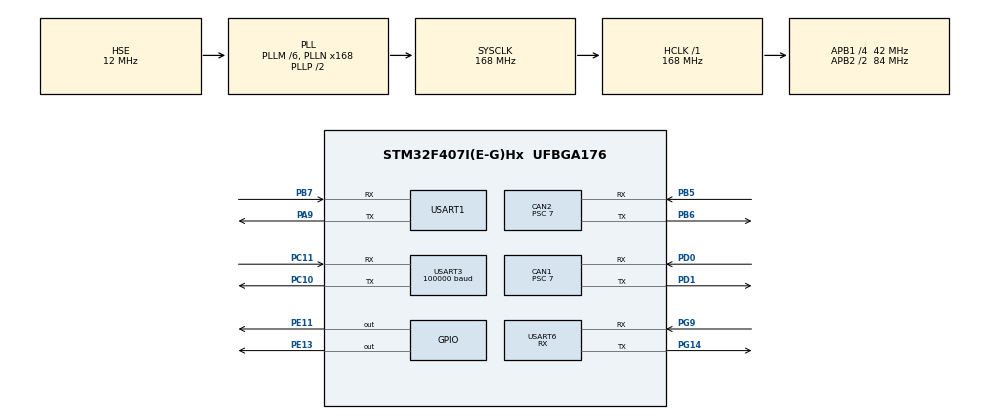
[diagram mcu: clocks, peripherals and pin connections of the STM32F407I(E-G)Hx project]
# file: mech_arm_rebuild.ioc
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CAN1.BS1=CAN_BS1_3TQ
CAN1.BS2=CAN_BS2_2TQ
CAN1.CalculateBaudRate=999999
CAN1.CalculateTimeBit=1000
CAN1.CalculateTimeQuantum=166.66666666666669
CAN1.Prescaler=7
CAN2.BS1=CAN_BS1_3TQ
CAN2.BS2=CAN_BS2_2TQ
CAN2.CalculateBaudRate=999999
CAN2.CalculateTimeBit=1000
CAN2.CalculateTimeQuantum=166.66666666666669
CAN2.Prescaler=7
Dma.Request0=USART3_RX
Dma.Request1=USART6_RX
Dma.USART3_RX.0.Direction=DMA_PERIPH_TO_MEMORY
Dma.USART3_RX.0.FIFOMode=DMA_FIFOMODE_DISABLE
Dma.USART3_RX.0.Instance=DMA1_Stream1
Dma.USART3_RX.0.MemDataAlignment=DMA_MDATAALIGN_BYTE
Dma.USART3_RX.0.MemInc=DMA_MINC_ENABLE
Dma.USART3_RX.0.Mode=DMA_NORMAL
Dma.USART3_RX.0.PeriphDataAlignment=DMA_PDATAALIGN_BYTE
Dma.USART3_RX.0.PeriphInc=DMA_PINC_DISABLE
Dma.USART3_RX.0.Priority=DMA_PRIORITY_LOW
Dma.USART6_RX.1.Direction=DMA_PERIPH_TO_MEMORY
Dma.USART6_RX.1.FIFOMode=DMA_FIFOMODE_DISABLE
Dma.USART6_RX.1.Instance=DMA2_Stream1
Dma.USART6_RX.1.MemDataAlignment=DMA_MDATAALIGN_BYTE
Dma.USART6_RX.1.MemInc=DMA_MINC_ENABLE
Dma.USART6_RX.1.Mode=DMA_NORMAL
Dma.USART6_RX.1.PeriphDataAlignment=DMA_PDATAALIGN_BYTE
Dma.USART6_RX.1.PeriphInc=DMA_PINC_DISABLE
Dma.USART6_RX.1.Priority=DMA_PRIORITY_LOW
Mcu.Family=STM32F4
Mcu.Name=STM32F407I(E-G)Hx
Mcu.Package=UFBGA176
NVIC.CAN1_RX0_IRQn=true\:0\:0\:false\:false\:true\:true\:true\:true
NVIC.CAN1_TX_IRQn=true\:0\:0\:false\:false\:true\:true\:true\:true
NVIC.CAN2_TX_IRQn=true\:0\:0\:false\:false\:true\:true\:true\:true
NVIC.DMA1_Stream1_IRQn=true\:0\:0\:false\:false\:true\:false\:true\:true
NVIC.DMA2_Stream1_IRQn=true\:0\:0\:false\:false\:true\:false\:true\:true
NVIC.PriorityGroup=NVIC_PRIORITYGROUP_4
NVIC.TIM3_IRQn=true\:0\:0\:false\:false\:true\:true\:true\:true
NVIC.TIM4_IRQn=true\:0\:0\:false\:false\:true\:true\:true\:true
NVIC.USART1_IRQn=true\:0\:0\:false\:false\:true\:true\:true\:true
NVIC.USART3_IRQn=true\:0\:0\:false\:false\:true\:true\:true\:true
NVIC.USART6_IRQn=true\:0\:0\:false\:false\:true\:true\:true\:true
PA13.Mode=Serial_Wire
PA13.Signal=SYS_JTMS-SWDIO
PA14.Mode=Serial_Wire
PA14.Signal=SYS_JTCK-SWCLK
PA9.Mode=Asynchronous
PA9.Signal=USART1_TX
PB5.Mode=CAN_Activate
PB5.Signal=CAN2_RX
PB6.Mode=CAN_Activate
PB6.Signal=CAN2_TX
PB7.Mode=Asynchronous
PB7.Signal=USART1_RX
PC10.Mode=Asynchronous
PC10.Signal=USART3_TX
PC11.Mode=Asynchronous
PC11.Signal=USART3_RX
PD0.Mode=CAN_Activate
PD0.Signal=CAN1_RX
PD1.Mode=CAN_Activate
PD1.Signal=CAN1_TX
PE11.Signal=GPIO_Output
PE13.Signal=GPIO_Output
PG14.Mode=Asynchronous
PG14.Signal=USART6_TX
PG9.Mode=Asynchronous
PG9.Signal=USART6_RX
PH0-OSC_IN.Mode=HSE-External-Oscillator
PH0-OSC_IN.Signal=RCC_OSC_IN
PH1-OSC_OUT.Mode=HSE-External-Oscillator
PH1-OSC_OUT.Signal=RCC_OSC_OUT
ProjectManager.HeapSize=0x200
ProjectManager.StackSize=0x400
ProjectManager.TargetToolchain=MDK-ARM V5.32
RCC.48MHZClocksFreq_Value=84000000
RCC.AHBFreq_Value=168000000
RCC.APB1CLKDivider=RCC_HCLK_DIV4
RCC.APB1Freq_Value=42000000
RCC.APB1TimFreq_Value=84000000
RCC.APB2CLKDivider=RCC_HCLK_DIV2
RCC.APB2Freq_Value=84000000
RCC.APB2TimFreq_Value=168000000
RCC.CortexFreq_Value=168000000
RCC.HCLKFreq_Value=168000000
RCC.HSE_VALUE=12000000
RCC.HSI_VALUE=16000000
RCC.LSE_VALUE=32768
RCC.PLLM=6
RCC.PLLN=168
RCC.PLLSourceVirtual=RCC_PLLSOURCE_HSE
RCC.SYSCLKFreq_VALUE=168000000
RCC.SYSCLKSource=RCC_SYSCLKSOURCE_PLLCLK
RCC.VCOOutputFreq_Value=336000000
TIM3.AutoReloadPreload=TIM_AUTORELOAD_PRELOAD_ENABLE
TIM3.Period=5000-1
TIM3.Prescaler=83
TIM4.AutoReloadPreload=TIM_AUTORELOAD_PRELOAD_ENABLE
TIM4.Period=1000-1
TIM4.Prescaler=83
USART1.VirtualMode=VM_ASYNC
USART3.BaudRate=100000
USART3.Parity=PARITY_EVEN
USART3.VirtualMode=VM_ASYNC
USART3.WordLength=WORDLENGTH_9B
USART6.Mode=MODE_RX
USART6.VirtualMode=VM_ASYNC
VP_TIM3_VS_ClockSourceINT.Mode=Internal
VP_TIM4_VS_ClockSourceINT.Mode=Internal
board=custom

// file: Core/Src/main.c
/* USER CODE BEGIN Header */
/**
  ******************************************************************************
  * @file           : main.c
  * @brief          : Main program body
  ******************************************************************************
  * @attention
  *
  * Copyright (c) 2025 STMicroelectronics.
  * All rights reserved.
  *
  * This software is licensed under terms that can be found in the LICENSE file
  * in the root directory of this software component.
  * If no LICENSE file comes with this software, it is provided AS-IS.
  *
  ******************************************************************************
  */
/* USER CODE END Header */
#include "main.h"
#include "can.h"
#include "dma.h"
#include "tim.h"
#include "usart.h"
#include "gpio.h"

/* USER CODE BEGIN Includes */
#include "app.h"
#include "gimbal.h"
#include "M3508.h"
#include "receive.h"

#include "bsp_can.h"
#include "bsp_tim.h"
#include "bsp_uart.h"
/* USER CODE END Includes */

void SystemClock_Config(void);

int main(void)
{

  /* MCU Configuration--------------------------------------------------------*/

  /* Reset of all peripherals, Initializes the Flash interface and the Systick. */
  HAL_Init();

  /* Configure the system clock */
  SystemClock_Config();

  /* Initialize all configured peripherals */
  MX_GPIO_Init();
  MX_DMA_Init();
  MX_CAN1_Init();
  MX_TIM4_Init();
  MX_USART1_UART_Init();
  MX_USART3_UART_Init();
  MX_TIM3_Init();
  MX_CAN2_Init();
  MX_USART6_UART_Init();
  /* USER CODE BEGIN 2 */

	bsp_can_init();

  gimbal_init(&gimbal_data, &M6020_Motor);
  bsp_uart_init();
	bsp_tim_init();
  /* USER CODE END 2 */

  /* Infinite loop */
  while (1)
  {

    /* USER CODE BEGIN 3 */
		HAL_Delay(1);
  }
  /* USER CODE END 3 */
}

void SystemClock_Config(void)
{
  RCC_OscInitTypeDef RCC_OscInitStruct = {0};
  RCC_ClkInitTypeDef RCC_ClkInitStruct = {0};

  /** Configure the main internal regulator output voltage
  */
  __HAL_RCC_PWR_CLK_ENABLE();
  __HAL_PWR_VOLTAGESCALING_CONFIG(PWR_REGULATOR_VOLTAGE_SCALE1);

  /** Initializes the RCC Oscillators according to the specified parameters
  * in the RCC_OscInitTypeDef structure.
  */
  RCC_OscInitStruct.OscillatorType = RCC_OSCILLATORTYPE_HSE;
  RCC_OscInitStruct.HSEState = RCC_HSE_ON;
  RCC_OscInitStruct.PLL.PLLState = RCC_PLL_ON;
  RCC_OscInitStruct.PLL.PLLSource = RCC_PLLSOURCE_HSE;
  RCC_OscInitStruct.PLL.PLLM = 6;
  RCC_OscInitStruct.PLL.PLLN = 168;
  RCC_OscInitStruct.PLL.PLLP = RCC_PLLP_DIV2;
  RCC_OscInitStruct.PLL.PLLQ = 4;
  if (HAL_RCC_OscConfig(&RCC_OscInitStruct) != HAL_OK)
  {
    Error_Handler();
  }

  /** Initializes the CPU, AHB and APB buses clocks
  */
  RCC_ClkInitStruct.ClockType = RCC_CLOCKTYPE_HCLK|RCC_CLOCKTYPE_SYSCLK
                              |RCC_CLOCKTYPE_PCLK1|RCC_CLOCKTYPE_PCLK2;
  RCC_ClkInitStruct.SYSCLKSource = RCC_SYSCLKSOURCE_PLLCLK;
  RCC_ClkInitStruct.AHBCLKDivider = RCC_SYSCLK_DIV1;
  RCC_ClkInitStruct.APB1CLKDivider = RCC_HCLK_DIV4;
  RCC_ClkInitStruct.APB2CLKDivider = RCC_HCLK_DIV2;

  if (HAL_RCC_ClockConfig(&RCC_ClkInitStruct, FLASH_LATENCY_5) != HAL_OK)
  {
    Error_Handler();
  }
}

/* USER CODE BEGIN 4 */
void motor_init()
{

}
/* USER CODE END 4 */

void Error_Handler(void)
{
  __disable_irq();
  while (1)
  {
  }
}
